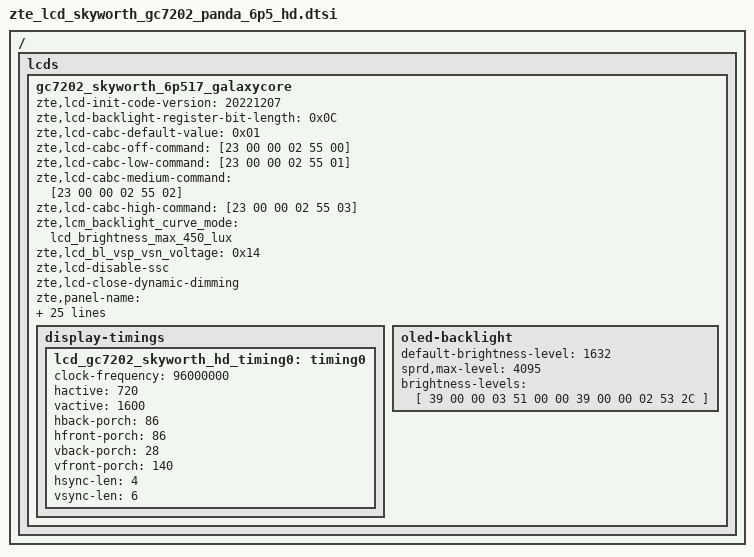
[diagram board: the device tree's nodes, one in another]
/ {
	fragment {
		target-path = "/";
		__overlay__ {
 lcds {
	gc7202_skyworth_6p517_galaxycore: gc7202_skyworth_6p517_galaxycore {
		zte,lcd-init-code-version = "20221207";
		zte,lcd-backlight-register-bit-length = <0x0C>;
		zte,lcd-cabc-default-value = <0x01>;
		zte,lcd-cabc-off-command = [23 00 00 02 55 00];
		zte,lcd-cabc-low-command = [23 00 00 02 55 01];
		zte,lcd-cabc-medium-command = [23 00 00 02 55 02];
		zte,lcd-cabc-high-command = [23 00 00 02 55 03];
		zte,lcm_backlight_curve_mode = "lcd_brightness_max_450_lux";
		zte,lcd_bl_vsp_vsn_voltage = <0x14>;
		zte,lcd-disable-ssc;
		zte,lcd-close-dynamic-dimming;
		zte,panel-name = "gc7202_skyworth_6p517_galaxycore";
		zte,lcd-delay-open-bl-value = <34>;

		sprd,dsi-work-mode = <1>; /* video burst mode*/
		sprd,dsi-lane-number = <4>;
		sprd,dsi-color-format = "rgb888";

		sprd,phy-bit-clock = <700000>;	/* kbps */
		sprd,phy-escape-clock = <20000>;/* kHz */

		sprd,width-mm = <67932>;
		sprd,height-mm = <150960>;

		sprd,esd-check-enable = <1>;/* 0:close , 1:open */
		sprd,esd-check-mode = <1>;/* 0:REG ,1:TE  */
		sprd,esd-check-period = <1000>;
		sprd,esd-check-register = <0x0A>;
		sprd,esd-check-value = <0x9C>;

		sprd,reset-on-sequence = <1 10>, <0 10>, <1 35>, <0 10>, <1 10>, <0 10>, <1 10>, <0 10>, <1 30>;
		sprd,reset-off-sequence = <1 5>;
		sprd,initial-command = [
39 00 00 04 FF 55 AA 66
39 00 00 02 FF 20
39 00 00 02 FB 00
39 00 00 02 FF 21
39 00 00 02 FB 00
39 00 00 02 FF 22
39 00 00 02 FB 00
39 00 00 02 FF 23
39 00 00 02 FB 00
39 00 00 02 FF 24
39 00 00 02 FB 00
39 00 00 02 FF 26
39 00 00 02 FB 00
39 00 00 02 FF 27
39 00 00 02 FB 00
39 00 00 02 FF A3
39 00 00 02 FB 00
39 00 00 02 FF B3
39 00 00 02 FB 00
39 00 00 02 FF C3
39 00 00 02 FB 00
39 00 00 02 FF 22
39 00 00 02 E4 01
39 00 00 02 01 06
39 00 00 02 02 40
39 00 00 02 25 08
39 00 00 02 26 00
39 00 00 02 2E 6F
39 00 00 02 2F 00
39 00 00 02 36 09
39 00 00 02 37 00
39 00 00 02 3F 6F
39 00 00 02 40 00
39 00 00 02 0E 33
39 00 00 02 DC 00
39 00 00 02 08 40
39 00 00 02 FF 21
39 00 00 02 01 25
39 00 00 02 02 05
39 00 00 02 03 1A
39 00 00 02 04 25
39 00 00 02 05 25
39 00 00 02 06 01
39 00 00 02 07 0F
39 00 00 02 08 0D
39 00 00 02 09 0B
39 00 00 02 0A 09
39 00 00 02 0B 23
39 00 00 02 0C 23
39 00 00 02 0D 25
39 00 00 02 0E 25
39 00 00 02 0F 25
39 00 00 02 10 25
39 00 00 02 11 25
39 00 00 02 12 25
39 00 00 02 13 25
39 00 00 02 14 25
39 00 00 02 15 25
39 00 00 02 16 25
39 00 00 02 17 25
39 00 00 02 18 04
39 00 00 02 19 1A
39 00 00 02 1A 25
39 00 00 02 1B 25
39 00 00 02 1C 00
39 00 00 02 1D 0E
39 00 00 02 1E 0C
39 00 00 02 1F 0A
39 00 00 02 20 08
39 00 00 02 21 23
39 00 00 02 22 23
39 00 00 02 23 25
39 00 00 02 24 25
39 00 00 02 25 25
39 00 00 02 26 25
39 00 00 02 27 25
39 00 00 02 28 25
39 00 00 02 29 25
39 00 00 02 2A 25
39 00 00 02 2B 25
39 00 00 02 2D 25
39 00 00 02 45 33
39 00 00 02 7E 03
39 00 00 02 C2 85
39 00 00 02 7F 21
39 00 00 02 8B 21
39 00 00 02 80 01
39 00 00 02 8C 1A
39 00 00 02 81 1A
39 00 00 02 8D 01
39 00 00 02 AF 40
39 00 00 02 B0 40
39 00 00 02 83 04
39 00 00 02 8F 04
39 00 00 02 84 55
39 00 00 02 90 55
39 00 00 02 85 55
39 00 00 02 91 55
39 00 00 02 87 00
39 00 00 02 93 00
39 00 00 02 2E 00
39 00 00 02 88 A7
39 00 00 02 89 20
39 00 00 02 8A 33
39 00 00 02 94 A7
39 00 00 02 95 20
39 00 00 02 96 33
39 00 00 02 46 53
39 00 00 02 4C 53
39 00 00 02 5E 41
39 00 00 02 64 41
39 00 00 02 82 50
39 00 00 02 8E 50
39 00 00 02 47 02
39 00 00 02 4D 01
39 00 00 02 48 01
39 00 00 02 4E 02
39 00 00 02 5F 21
39 00 00 02 65 22
39 00 00 02 60 22
39 00 00 02 66 21
39 00 00 02 76 40
39 00 00 02 77 40
39 00 00 02 7A 44
39 00 00 02 7B 44
39 00 00 02 49 55
39 00 00 02 4A 55
39 00 00 02 4F 55
39 00 00 02 50 55
39 00 00 02 61 55
39 00 00 02 62 55
39 00 00 02 67 55
39 00 00 02 68 55
39 00 00 02 C6 56
39 00 00 02 D1 13
39 00 00 02 FF B3
39 00 00 02 4A 00
39 00 00 02 7D 28
39 00 00 02 51 51
39 00 00 02 5B 00
39 00 00 02 48 23
39 00 00 02 7C 88
39 00 00 02 3E 03
39 00 00 02 3F 7f
39 00 00 02 5E 10
39 00 00 02 58 84
39 00 00 02 FF 20
39 00 00 02 29 01
39 00 00 02 2D 1F
39 00 00 02 02 27
39 00 00 02 03 27
39 00 00 02 04 45
39 00 00 02 05 45
39 00 00 02 0A 1B
39 00 00 02 0B 1B
39 00 00 02 0C 4B
39 00 00 02 0D 4B
39 00 00 02 77 74
39 00 00 02 78 74
39 00 00 02 A5 00
39 00 00 02 A6 FF
39 00 00 02 A9 00
39 00 00 02 AA FF
39 00 00 02 AD 00
39 00 00 02 AE FF
39 00 00 02 B1 00
39 00 00 02 B2 FF
39 00 00 02 C3 00
39 00 00 02 C4 5F
39 00 00 02 C5 00
39 00 00 02 C6 5F
39 00 00 02 B3 00
39 00 00 02 B4 20
39 00 00 02 B5 00
39 00 00 02 B6 DC
39 00 00 02 C7 00
39 00 00 02 C8 93
39 00 00 02 C9 00
39 00 00 02 CA 93
39 00 00 02 B7 00
39 00 00 02 B8 20
39 00 00 02 B9 01
39 00 00 02 BA 90
39 00 00 02 CB 00
39 00 00 02 CC 90
39 00 00 02 BB 00
39 00 00 02 BC 16
39 00 00 02 BD 00
39 00 00 02 BE 12
39 00 00 02 D5 0E
39 00 00 02 7E 01
39 00 00 02 7F 00
39 00 00 02 80 01
39 00 00 02 81 00
39 00 00 02 82 00
39 00 00 02 83 04
39 00 00 02 84 04
39 00 00 02 85 01
39 00 00 02 86 8B
39 00 00 02 87 01
39 00 00 02 88 8B
39 00 00 02 8A 03
39 00 00 02 8B 03
39 00 00 02 18 44
39 00 00 02 17 51
39 00 00 02 12 A2
39 00 00 02 15 4C
39 00 00 02 A3 44
39 00 00 02 A7 44
39 00 00 02 D3 05
39 00 00 02 24 99
39 00 00 02 25 16
39 00 00 02 FF 23
39 00 00 11 01 00 00 00 14 00 53 00 7E 00 95 00 B0 00 BE 00 D0
39 00 00 11 02 00 E0 01 0E 01 32 01 61 01 80 01 B4 01 DD 01 DE
39 00 00 11 03 02 0A 02 44 02 6B 02 A0 02 C4 02 F6 03 06 03 18
39 00 00 0d 04 03 2B 03 44 03 62 03 88 03 C5 03 FF
39 00 00 11 05 00 00 00 14 00 53 00 7E 00 95 00 B0 00 BE 00 D0
39 00 00 11 06 00 E0 01 0E 01 32 01 61 01 80 01 B4 01 DD 01 DE
39 00 00 11 07 02 0A 02 44 02 6B 02 A0 02 C4 02 F6 03 06 03 18
39 00 00 0d 08 03 2B 03 44 03 62 03 88 03 C5 03 FF
39 00 00 11 09 00 00 00 14 00 53 00 7E 00 95 00 B0 00 BE 00 D0
39 00 00 11 0A 00 E0 01 0E 01 32 01 61 01 80 01 B4 01 DD 01 DE
39 00 00 11 0B 02 0A 02 44 02 6B 02 A0 02 C4 02 F6 03 06 03 18
39 00 00 0d 0C 03 2B 03 44 03 62 03 88 03 C5 03 FF
39 00 00 11 0D 00 00 00 14 00 53 00 7E 00 95 00 B0 00 BE 00 D0
39 00 00 11 0E 00 E0 01 0E 01 32 01 61 01 80 01 B4 01 DD 01 DE
39 00 00 11 0F 02 0A 02 44 02 6B 02 A0 02 C4 02 F6 03 06 03 18
39 00 00 0d 10 03 2B 03 44 03 62 03 88 03 C5 03 FF
39 00 00 11 11 00 00 00 14 00 53 00 7E 00 95 00 B0 00 BE 00 D0
39 00 00 11 12 00 E0 01 0E 01 32 01 61 01 80 01 B4 01 DD 01 DE
39 00 00 11 13 02 0A 02 44 02 6B 02 A0 02 C4 02 F6 03 06 03 18
39 00 00 0d 14 03 2B 03 44 03 62 03 88 03 C5 03 FF
39 00 00 11 15 00 00 00 14 00 53 00 7E 00 95 00 B0 00 BE 00 D0
39 00 00 11 16 00 E0 01 0E 01 32 01 61 01 80 01 B4 01 DD 01 DE
39 00 00 11 17 02 0A 02 44 02 6B 02 A0 02 C4 02 F6 03 06 03 18
39 00 00 0d 18 03 2B 03 44 03 62 03 88 03 C5 03 FF
39 00 00 02 B9 31
39 00 00 02 B8 b7
39 00 00 02 35 16
39 00 00 02 36 0C
39 00 00 02 30 00
39 00 00 11 1F 0a 00 20 00 44 00 70 00 A8 00 e6 00 0a 00 20 00
39 00 00 09 20 44 00 70 00 A8 00 FF 00
39 00 00 11 21 a7 00 b2 00 c0 00 cd 00 dA 00 f3 00 d4 00 e4 00
39 00 00 09 22 ec 00 F1 00 F1 00 FF 00
39 00 00 11 23 00 00 00 00 00 00 00 00 00 00 00 00 00 00 00 00
39 00 00 09 24 00 00 00 00 00 00 00 00
39 00 00 02 2E 00
39 00 00 02 2D 61
39 00 00 02 32 01
39 00 00 02 33 05
39 00 00 02 FF 20
39 00 00 02 50 00
39 00 00 02 51 22
39 00 00 02 FF 26
39 00 00 05 1D 0c 00 00 00
39 00 00 02 FF A3
39 00 00 02 FA 01
39 00 00 02 35 00
39 00 00 02 45 10
39 00 00 02 05 05
39 00 00 02 2B FB
39 00 00 02 FF 10
39 00 00 03 51 00 00
39 00 00 02 53 2C
39 00 00 02 36 08
39 00 00 02 69 00
39 00 00 02 35 00
15 00 00 02 ff b3
15 00 00 02 61 be
39 00 00 02 FF 10
05 78 00 01 11
05 32 00 01 29
			];
		sprd,sleep-in-command = [
23 00 00 02 53 28
39 00 00 03 51 00 00
39 00 00 04 FF 55 AA 66
23 00 00 02 FF 20
23 00 00 02 4A 01
23 00 00 02 48 10
23 00 00 02 49 00
23 00 00 02 FF 21
23 05 00 02 D1 00
23 00 00 02 FF A3
23 00 00 02 0F 01
23 05 00 02 0E 03
23 00 00 02 FF 10
23 32 00 02 28 00
23 00 00 02 FF B3
23 32 00 02 61 BE
23 00 00 02 FF 10
23 78 00 02 10 00
23 00 00 02 FF B3
23 32 00 02 61 00
23 00 00 02 FF A3
23 00 00 02 0F 00
23 05 00 02 0E 00
39 00 00 04 FF 55 AA 66
23 00 00 02 FF 26
23 00 00 03 1D 2A 80
23 00 00 02 FF B3
23 00 00 02 04 16
23 00 00 02 01 99
23 05 00 02 10 09
23 00 00 02 FF C3
23 0A 00 02 12 01
			];
		sprd,sleep-in-gesture-command = [
23 00 00 02 53 28
39 00 00 03 51 00 00
39 00 00 04 FF 55 AA 66
23 00 00 02 FF 20
23 00 00 02 4A 01
23 00 00 02 48 10
23 00 00 02 49 00
23 00 00 02 FF 21
23 00 00 02 D1 00
23 00 00 02 FF 10
23 32 00 02 28 00
23 00 00 02 FF B3
23 32 00 02 61 BE
23 00 00 02 FF 10
23 78 00 02 10 00
23 00 00 02 FF B3
23 32 00 02 61 00
			];
		sprd,sleep-out-command = [
			05 78 00 01 11
			05 32 00 01 29
			];

		display-timings {
			lcd_gc7202_skyworth_hd_timing0: timing0 {
			clock-frequency = <96000000>;
			hactive = <720>;
			vactive = <1600>;
			hback-porch = <86>;
			hfront-porch = <86>;
			vback-porch = <28>;
			vfront-porch = <140>;
			hsync-len = <4>;
			vsync-len = <6>;
			};
		};

		oled-backlight {
			default-brightness-level = <1632>;
			sprd,max-level = <4095>;
			brightness-levels = [
				39 00 00 03 51 00 00
				39 00 00 02 53 2C
			];
		};
	};
};};
};};

